AUTOSAR XML (schema 4-2-2)
package /AUTOLIV/SoftwareComponents/MIC
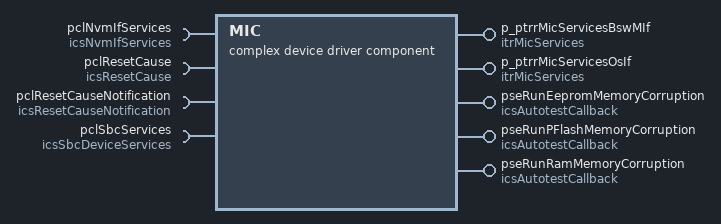
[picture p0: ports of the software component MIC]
  complex device driver sw component type MIC: category=BSW_Complex_Device_Drivers
    provide port p_ptrrMicServicesBswMIf: provided-interface=itrMicServices  # # Architecture Element ID - ARCH_SW_MIC_p_ptrrMicServicesBswMIf_MIC_Init # Description - The interface will call the MIC_Init runnable during initialization sequence - The runnable will control the MMC peripheral and RAM_NO_INIT data and apply (if possible) a backup strategy in order to restore the memory usage. # Data Flow ## Inputs ## Outputs # Linked Runnable - MIC_Init #Traceability FUSA_SM_S32K1XXSM_227, FUSA_SM_S32K1XXSM_235
    provide port p_ptrrMicServicesOsIf: provided-interface=itrMicServices  # # Architecture Element ID - ARCH_SW_MIC_p_ptrrMicServicesOsIf_MIC_HardFaultException # Description - The interface will call the MIC_HardFaultException runnable in case of CPU Hard Fault. - The runnable will manage ECC errors if pressent. # Data Flow ## Inputs ## Outputs # Linked Runnable - MIC_HardFaultException #Traceability ---------------------------------------------------------------------------------------------- # Architecture Element ID - ARCH_SW_MIC_p_ptrrMicServicesOsIf_MIC_MIC_BusFaultException # Description - The interface will call the MIC_BusFaultException runnable in case of CPU Bus Fault. - The runnable will manage ECC errors if pressent. # Data Flow ## Inputs ## Outputs # Linked Runnable - MIC_BusFaultException #Traceability ---------------------------------------------------------------------------------------------- # Architecture Element ID - ARCH_SW_MIC_p_ptrrMicServicesOsIf_MIC_MIC_HardFaultHandlerHll # Description - The interface will call the MIC_BusFaultException runnable in case of CPU HardFault. - The runnable will manage ECC errors if pressent. # Data Flow ## Inputs {Instruction address} ## Outputs # Linked Runnable - MIC_BusFaultException #Traceability
    4 x require port:
      pclNvmIfServices: required-interface=icsNvmIfServices  # # Architecture Element ID - ARCH_SW_MIC_pclNvmIfServices_SetRamBlockStatus # Description - The NvmIfServices_SetRamBlockStatus interface will set a flag, flag used to notify that the ECC Counters Block has to be recorded in the EEPROM during the shutdown. (The writhing procces will be done in NvM_WriteAll();) # Data Flow ## Inputs - {ECC Counter} ## Outputs - {Value of flag} # Linked Runnable - MIC_Autotest_RunRamMemoryCorruption - MIC_Autotest_RunPFlashMemoryCorruption - MIC_Autotest_RunEepromMemoryCorruption #Traceability DOM_eCS_TF_H_183, DOM_eCS_TF_H_184, DOM_eCS_TF_H_188
        required-com-specs:
          GetNvmBlockLength
          GetNvmBlockStatus
          ReadBlockByAddress
          RestorePRAMBlockDefaults
          SetRamBlockStatus
          WriteBlockByAddress
          WriteNvmBlock
      pclResetCause: required-com-specs=[DetermineResetCause, GetResetCause], required-interface=icsResetCause  # # Architecture Element ID - ARCH_SW_MIC_pclResetCause_GetResetCause # Description - The GetResetCause interface will set the active reset cause. - In case of an ECC Error in RAM, {Reset Cause} will be KU32_ECC_RAM_NOTIFICATION; - In case of an ECC error in Flex RAM, {Reset Cause} will be KU32_ECC_RAM_NOTIFICATION; - In case of an ECC in Stack RAM, {Reset Cause} will be KU32_ECC_RAM_NOTIFICATION; - In case of an ECC in Default EEPROM, {Reset Cause} will be KU32_ECC_PFLASH_NOTIFICATION; - In case of an ECC in Calibration FLASH , {Reset Cause} will be KU32_ECC_PFLASH_NOTIFICATION; - In case of an ECC in Program FLASH, {Reset Cause} will be KU32_ECC_PFLASH_NOTIFICATION; - In case of an ECC in Emulated EEPROM that the FLS did not recognize, {Reset Cause} will be KU32_ECC_E2P_NOTIFICATION; - In case of an ECC error in an unknown location, {Reset Cause} will be KU32_ECC_UNIDENTIFIED_NOTIFICATION; - In case of a machine exception occurs, {Reset Cause} will be KU32_MACHINE_EXCEPTION_NOTIFICATION; - In case of a OS exception occurs, {Reset Cause} will be KU32_OS_EXCEPTION_NOTIFICATION; # Data Flow ## Inputs ## Outputs - {Reset Cause} can be: - KU32_ECC_RAM_NOTIFICATION - KU32_MACHINE_EXCEPTION_NOTIFICATION - KU32_OS_EXCEPTION_NOTIFICATION - KU32_ECC_PFLASH_NOTIFICATION - KU32_ECC_E2P_NOTIFICATION - KU32_ECC_UNIDENTIFIED_NOTIFICATION # Linked Runnable MIC_Autotest_RunRamMemoryCorruption MIC_Autotest_RunPFlashMemoryCorruption MIC_Autotest_RunEepromMemoryCorruption #Traceability FUSA_SM_S32K1XXSM_237; FUSA_SM_S32K1XXSM_404; FUSA_SM_S32K1XXSM_423
      pclResetCauseNotification: client-com-spec=NotifyResetCause, required-interface=icsResetCauseNotification  # # Architecture Element ID - ARCH_SW_MIC_pclResetCauseNotification_NotifyResetCause # Description - The ResetCauseNotification_NotifyResetCause interface will notify active reset cause. # Data Flow ## Inputs - {Reset Cause} can be : - KU32_ECC_RAM_NOTIFICATION - KU32_MACHINE_EXCEPTION_NOTIFICATION - KU32_OS_EXCEPTION_NOTIFICATION - KU32_ECC_PFLASH_NOTIFICATION - KU32_ECC_E2P_NOTIFICATION - KU32_ECC_UNIDENTIFIED_NOTIFICATION ## Outputs # Linked Runnable - MIC_Init - MIC_HardFaultException - MIC_BusFaultException #Traceability FUSA_SM_S32K1XXSM_237
      pclSbcServices: required-com-specs=[SBC_Reset, SBC_Shutdown, GetSbcStatus], required-interface=icsSbcDeviceServices  # # Architecture Element ID - ARCH_SW_MIC_pclSbcServices_SBC_Reset # Description - The SBC_Reset runnable shall be called in the MIC_HardFaultException runnable in order to reset the ECU # Data Flow ## Inputs ## Outputs # Linked Runnable - MIC_BusFaultException - MIC_HardFaultException #Traceability
    provide port pseRunEepromMemoryCorruption: server-com-spec{operation=AutotestCallback, queue-length=1}, provided-interface=icsAutotestCallback  # # Architecture Element ID - ARCH_SW_MIC_pseRunEepromMemoryCorruption_MIC_Autotest_RunEepromMemoryCorruption # Description - The runnable shall be called to provide the result of Eeprom Memory Corruption Autotest. - Eeprom Memory Corruption Autotest will check if an ECC was detected in Eeprom memory area. - If an ECC is detected in Eeprom memory area the {Test Result} will be TEST_NOK. - If an ECC is NOT detected in Eeprom memory area the {Test Result} will be TEST_OK. # Data Flow ## Inputs ## Outputs - {Test Result} can be: - TEST_NOT_DECIDED - TEST_NOK - TEST_OK OK/nok/not_decided # Linked Runnable - MIC_Autotest_RunEepromMemoryCorruption #Traceability DOM_eCS_TF_H_199, DOM_eCS_TF_H_205, DOM_eCS_TF_H_206, DOM_eCS_TF_H_207
    provide port pseRunPFlashMemoryCorruption: server-com-spec{operation=AutotestCallback, queue-length=1}, provided-interface=icsAutotestCallback  # # Architecture Element ID - ARCH_SW_MIC_pseRunPFlashMemoryCorruption_MIC_Autotest_RunPFlashMemoryCorruption # Description - The runnable shall be called to provide the result of PFlash Memory Corruption Autotest. - PFlash Memory Corruption Autotestcheck if an ECC was detected in PFLASH memory area. - If an ECC is detected in PFLASH memory area the {Test Result} will be TEST_NOK. - If an ECC is NOT detected in PFLASH memory area the {Test Result} will be TEST_OK. # Data Flow ## Inputs ## Outputs - {Test Result} can be: - TEST_NOT_DECIDED - TEST_NOK - TEST_OK # Linked Runnable - MIC_Autotest_RunPFlashMemoryCorruption #Traceability DOM_eCS_TF_H_164, DOM_eCS_TF_H_171, DOM_eCS_TF_H_173, DOM_eCS_TF_H_172, DOM_eCS_TF_H_177
    provide port pseRunRamMemoryCorruption: server-com-spec{operation=AutotestCallback, queue-length=1}, provided-interface=icsAutotestCallback  # # Architecture Element ID - ARCH_SW_MIC_pseRunRamMemoryCorruption_MIC_Autotest_RunRamMemoryCorruption # Description - The runnable shall be called to provide the result of Ram Memory Corruption Autotest. - Ram Memory Corruption Autotest check if an ECC was detected in RAM memory area. - If an ECC is detected in RAM memory area the {Test Result} will be TEST_NOK. - If an ECC is NOT detected in RAM memory area the {Test Result} will be TEST_OK. # Data Flow ## Inputs ## Outputs - {Test Result} can be: - TEST_NOT_DECIDED - TEST_NOK - TEST_OK # Linked Runnable - MIC_Autotest_RunRamMemoryCorruption #Traceability DOM_eCS_TF_H_194, DOM_eCS_TF_H_195, DOM_eCS_TF_H_196, FUSA_SM_S32K1XXSM_235, FUSA_SM_S32K1XXSM_237
  trigger interface itrMicServices
    trigger MIC_BusFaultException: trigger-period={cse-code=1000, cse-code-factor=0}
    trigger MIC_HardFaultException: trigger-period={cse-code=1000, cse-code-factor=0}
    trigger MIC_Init: trigger-period={cse-code=1000, cse-code-factor=0}
